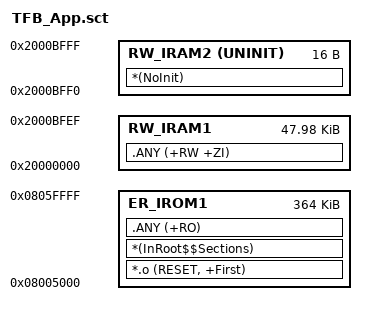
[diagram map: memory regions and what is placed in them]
; *************************************************************
; *** Scatter-Loading Description File generated by uVision ***
; *************************************************************

LR_IROM1 0x08005000 0x0005B000  {    ; load region size_region
  ER_IROM1 0x08005000 0x0005B000 {  ; load address = execution address
   *.o (RESET, +First)
   *(InRoot$$Sections)
   .ANY (+RO)
  }
  
  RW_IRAM1 0x20000000 0x0000BFF0  {  ; RW data
   .ANY (+RW +ZI)
  }
  
  RW_IRAM2  0x2000BFF0 UNINIT 0x00000010 {  ; RW data
   *(NoInit)
  }    
}

